# DA1469x register map
Vendor: Dialog; Series: DA1469x; File version: 1.2
CPU: CM33 r1p0, little endian, no MPU, FPU, 3 interrupt priority bits
Registers are 32-bit, read-write, reset 0x0 unless marked. A register's access mark holds for its fields unless they carry their own. Offsets are from the block's base; [hi:lo] are bit positions.

## APU — APU registers
Base 0x50030600
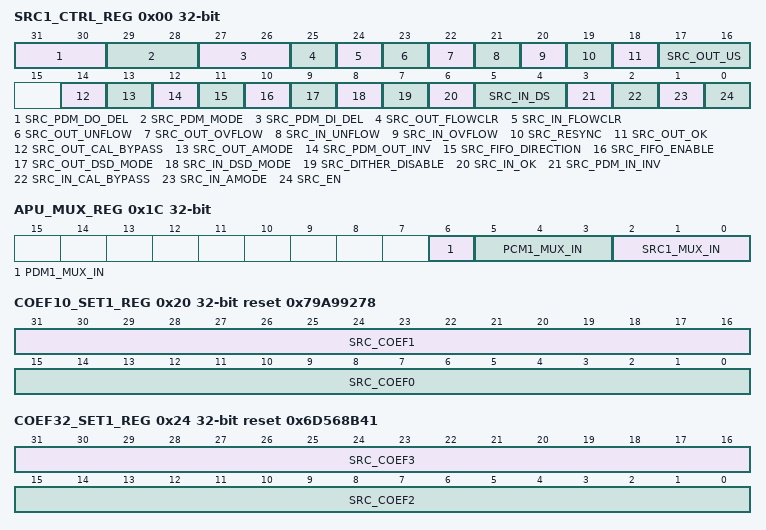
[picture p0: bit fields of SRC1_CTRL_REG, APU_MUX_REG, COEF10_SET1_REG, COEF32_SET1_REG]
0x00 SRC1_CTRL_REG (reset mask 0x7FFFFFFF) — SRC1 control register
  [31:30] SRC_PDM_DO_DEL — PDM_DO output delay line (typical) 0: no delay 1: 8 ns 2: 12 ns 3: 16 ns
  [29:28] SRC_PDM_MODE — PDM Output mode selection on PDM_DO1 00: No output 01: Right channel (data from SRC1_IN_REG) 10: Left channel (data from SRC2_IN_REG) 11: Left and Right channel
  [27:26] SRC_PDM_DI_DEL — PDM_DI input delay line (typical) 0: no delay 1: 4 ns 2: 8 ns 3: 12 ns
  [25] SRC_OUT_FLOWCLR wo — Writing a 1 clears the SRC1_OUT Overflow/underflow bits 23-22. No more over/underflow indications while bit is 1. Keep 1 until the over/under flow bit is cleared
  [24] SRC_IN_FLOWCLR wo — Writing a 1 clears the SRC1_IN Overflow/underflow bits 21-20. No more over/underflow indications while bit is 1. Keep 1 until the over/under flow bit is cleared
  [23] SRC_OUT_UNFLOW ro — 1 = SRC1_OUT Underflow occurred
  [22] SRC_OUT_OVFLOW ro — 1 = SRC1_OUT Overflow occurred
  [21] SRC_IN_UNFLOW ro — 1 = SRC1_IN Underflow occurred
  [20] SRC_IN_OVFLOW ro — 1 = SRC1_IN Overflow occurred
  [19] SRC_RESYNC wo — 1 = SRC will restart synchronisation
  [18] SRC_OUT_OK ro — SRC1_OUT Status 0: acquisition in progress 1: acquisition ready (In manual mode this bit is always 1)
  [17:16] SRC_OUT_US — SRC1_OUT UpSampling IIR filters setting 00: for sample rates up-to 48kHz 01: for sample rates of 96kHz 10: reserved 11: for sample rates of 192kHz
  [14] SRC_OUT_CAL_BYPASS — SRC1_OUT1 upsampiling filter bypass 0:Do not bypass 1:Bypass filter
  [13] SRC_OUT_AMODE — SRC1_OUT1 Automatic Conversion mode 0:Manual mode 1:Automatic mode
  [12] SRC_PDM_OUT_INV — Swap the left and the right output PDM channel
  [11] SRC_FIFO_DIRECTION — 0 = SRC fifo is used to store samples from memory to SRC 1 = SRC fifo is used to store sample from SRC to memory
  [10] SRC_FIFO_ENABLE — 0 = fifo disable. On each src request, one sample is serviced 1 = fifo enable. Fifo is used to store samples from / to src SRC supports only DMA burst size 4 when fifo is enable else no burst
  [9] SRC_OUT_DSD_MODE — 0 = SRC1 OUT PDM mode 1 = SRC1 OUT DSD mode
  [8] SRC_IN_DSD_MODE — 0: SRC1 IN PDM mode 1: SRC1 IN DSD mode
  [7] SRC_DITHER_DISABLE — Dithering feature 0: Enable 1: Disable
  [6] SRC_IN_OK ro — SRC1_IN status 0: Acquisition in progress 1: Acquisition ready
  [5:4] SRC_IN_DS — SRC1_IN UpSampling IIR filters setting 00: for sample rates up-to 48kHz 01: for sample rates of 96kHz 10: reserved 11: for sample rates of 192kHz
  [3] SRC_PDM_IN_INV — Swap the left and the right input PDM channel
  [2] SRC_IN_CAL_BYPASS — SRC1_IN upsampeling filter bypass 0: Do not bypass 1: Bypass filter
  [1] SRC_IN_AMODE — SRC1_IN Automatic conversion mode 0: Manual mode 1: Automatic mode
  [0] SRC_EN — SRC1_IN and SRC1_OUT enable 0: disabled 1: enabled
0x04 SRC1_IN_FS_REG — SRC1 Sample input rate
  [23:0] SRC_IN_FS — SRC_IN Sample rate SRC_IN_FS = SRC_DIV*4096*Sample_rate/100 Sample_rate upper limit is 192kHz. For 96kHz and 192kHz SRC_CTRLx_REG[SRC_IN_DS] must be set as shown below: (for SRC_DIV=1) Sample_rate SRC_IN_FS SRC_IN_DS Audio bandwidth 8000 Hz 0x050000 0 4000 Hz 11025 Hz 0x06E400 0 5512 Hz 16000 Hz 0x0A0000 0 8000 Hz 22050 Hz 0x0DC800 0 11025 Hz 32000 Hz 0x140000 0 16000 Hz 44100 Hz 0x1B9000 0 22050 Hz 48000 Hz 0x1E0000 0 24000 Hz 96000 Hz 0x1E0000 1 24000 Hz 192000 Hz 0x1E0000 3 24000 Hz In manual SRC mode, SRC_IN_FS can be set and adjusted to the desired sample rate at any time. In automatic mode the SRC returns the final sample rate as soon as SRC_IN_OK. Note that SRC_DS is not calculated in automatic mode and must be set manually automatic mode with Sample_rate of 96 and 192kHz.
0x08 SRC1_OUT_FS_REG — SRC1 Sample output rate
  [23:0] SRC_OUT_FS — SRC_OUT Sample rate SRC_OUT_FS = SRC_DIV*4096*Sample_rate/100 Sample_rate upper limit is 192kHz. For 96kHz and 192kHz SRC_CTRLx_REG[SRC_DS] must be set as shown below: (for SRC_DIV=1) Sample_rate SRC_OUT_FS SRC_OUT_DS Audio bandwidth 8000 Hz 0x050000 0 4000 Hz 11025 Hz 0x06E400 0 5512 Hz 16000 Hz 0x0A0000 0 8000 Hz 22050 Hz 0x0DC800 0 11025 Hz 32000 Hz 0x140000 0 16000 Hz 44100 Hz 0x1B9000 0 22050 Hz 48000 Hz 0x1E0000 0 24000 Hz 96000 Hz 0x1E0000 1 24000 Hz 192000 Hz 0x1E0000 3 24000 Hz In manual SRC mode, SRC_OUT_FS can be set and adjusted to the desired sample rate at any time. In automatic mode the SRC returns the final sample rate as soon as SRC_OUT_OK. Note that SRC_DS is not calculated in automatic mode and must be set manually automatic mode with Sample_rate of 96 and 192kHz.
0x0C SRC1_IN1_REG (reset mask 0x7FFFFFFF) — SRC1 data in 1
  [31:0] SRC_IN — SRC1_IN1
0x10 SRC1_IN2_REG (reset mask 0x7FFFFFFF) — SRC1 data in 2
  [31:0] SRC_IN — SRC1_IN2
0x14 SRC1_OUT1_REG (reset mask 0x7FFFFFFF) — SRC1 data out 1
  [31:0] SRC_OUT ro — SRC1_OUT1
0x18 SRC1_OUT2_REG (reset mask 0x7FFFFFFF) — SRC1 data out 2
  [31:0] SRC_OUT ro — SRC1_OUT2
0x1C APU_MUX_REG — APU mux register
  [6] PDM1_MUX_IN — PDM1 input mux 0 = SRC1_MUX_IN 1 = PDM input
  [5:3] PCM1_MUX_IN — PCM1 input mux 0 = off 1 = SRC1 output 2 = PCM output registers
  [2:0] SRC1_MUX_IN — SRC1 input mux 0 = off 1 = PCM output 2 = SRC1 input registers
0x20 COEF10_SET1_REG reset 0x79A99278 (reset mask 0x7FFFFFFF) — SRC coefficient 1,0 set 1
  [31:16] SRC_COEF1 — coefficient 1
  [15:0] SRC_COEF0 — coefficient 0
0x24 COEF32_SET1_REG reset 0x6D568B41 (reset mask 0x7FFFFFFF) — SRC coefficient 3,2 set 1
  [31:16] SRC_COEF3 — coefficient 3
  [15:0] SRC_COEF2 — coefficient 2
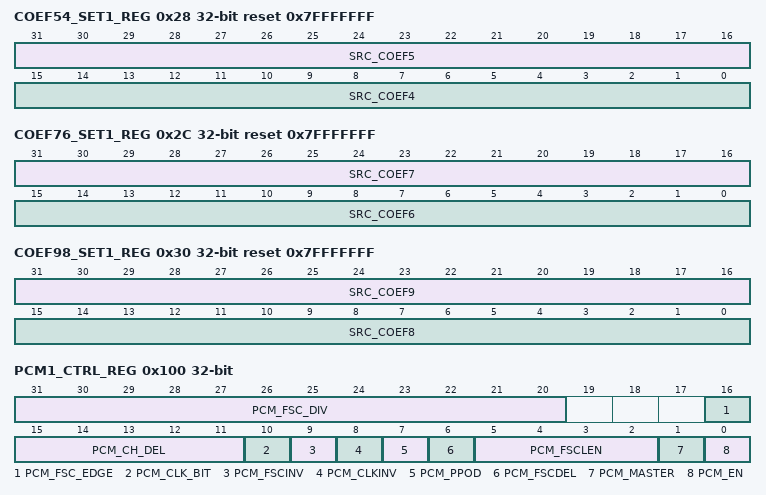
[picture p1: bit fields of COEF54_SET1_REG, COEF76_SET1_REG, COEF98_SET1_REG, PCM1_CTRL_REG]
0x28 COEF54_SET1_REG reset 0x7FFFFFFF (reset mask 0x7FFFFFFF) — SRC coefficient 5,4 set 1
  [31:16] SRC_COEF5 — coefficient 5
  [15:0] SRC_COEF4 — coefficient 4
0x2C COEF76_SET1_REG reset 0x7FFFFFFF (reset mask 0x7FFFFFFF) — SRC coefficient 7,6 set 1
  [31:16] SRC_COEF7 — coefficient 7
  [15:0] SRC_COEF6 — coefficient 6
0x30 COEF98_SET1_REG reset 0x7FFFFFFF (reset mask 0x7FFFFFFF) — SRC coefficient 9,8 set 1
  [31:16] SRC_COEF9 — coefficient 9
  [15:0] SRC_COEF8 — coefficient 8
0x34 COEF0A_SET1_REG reset 0x41F2 — SRC coefficient 10 set 1
  [15:0] SRC_COEF10 — coefficient 10
0x100 PCM1_CTRL_REG (reset mask 0x7FFFFFFF) — PCM1 Control register
  [31:20] PCM_FSC_DIV — PCM Framesync divider, Values 7-0xFFF. To divide by N, write N-1. (Minimum value N-1=7 for 8 bits PCM_FSC) Note if PCM_CLK_BIT=1, N must always be even
  [16] PCM_FSC_EDGE — 0: shift channels 1, 2, 3, 4, 5, 6, 7, 8 after PCM_FSC edge 1: shift channels 1, 2, 3, 4 after PCM_FSC edge shift channels 5, 6, 7, 8 after opposite PCM_FSC edge
  [15:11] PCM_CH_DEL — Channel delay in multiples of 8 bits
  [10] PCM_CLK_BIT — 0:One clock cycle per data bit 1:Two cloc cycles per data bit
  [9] PCM_FSCINV — 0: PCM FSC 1: PCM FSC inverted
  [8] PCM_CLKINV — 0:PCM CLK 1:PCM CLK inverted
  [7] PCM_PPOD — 0:PCM DO push pull 1:PCM DO open drain
  [6] PCM_FSCDEL — 0:PCM FSC starts one cycle before MSB bit 1:PCM FSC starts at the same time as MSB bit
  [5:2] PCM_FSCLEN — 0:PCM FSC length equal to 1 data bit N:PCM FSC length equal to N*8
  [1] PCM_MASTER — 0:PCM interface in slave mode 1:PCM interface in master mode
  [0] PCM_EN — 0:PCM interface disabled 1:PCM interface enabled
0x104 PCM1_IN1_REG (reset mask 0x7FFFFFFF) — PCM1 data in 1
  [31:0] PCM_IN ro — PCM1_IN1 bits 31-0
0x108 PCM1_IN2_REG (reset mask 0x7FFFFFFF) — PCM1 data in 2
  [31:0] PCM_IN ro — PCM1_IN2 bits 31-0
0x10C PCM1_OUT1_REG reset 0x7FFFFFFF (reset mask 0x7FFFFFFF) — PCM1 data out 1
  [31:0] PCM_OUT — PCM1_OUT1 bits 31-0
0x110 PCM1_OUT2_REG reset 0x7FFFFFFF (reset mask 0x7FFFFFFF) — PCM1 data out 2
  [31:0] PCM_OUT — PCM1_OUT2 bits 31-0
